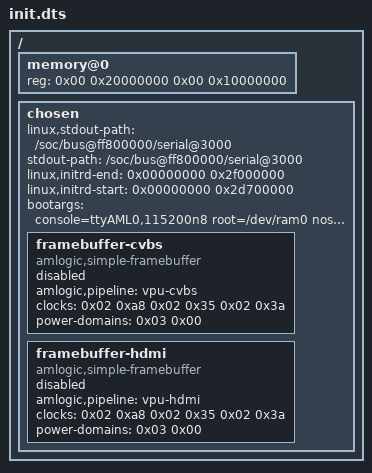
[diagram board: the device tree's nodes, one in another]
/ {
    /delete-node/ memory@0;
    /delete-node/ chosen;

    memory@0 {
		device_type = "memory";
		reg = <0x00 0x20000000 0x00 0x10000000>;
	};

	chosen {
		#address-cells = <0x02>;
		#size-cells = <0x02>;
		ranges;
        linux,stdout-path = "/soc/bus@ff800000/serial@3000";
        stdout-path = "/soc/bus@ff800000/serial@3000";
		linux,initrd-end = <0x00000000 0x2f000000>;
        linux,initrd-start = <0x00000000 0x2d700000>;
        bootargs = "console=ttyAML0,115200n8 root=/dev/ram0 nosmp rw loglevel=8 pci=nomsi earlyprintk=serial maxcpus=1";

		framebuffer-cvbs {
			compatible = "amlogic,simple-framebuffer\0simple-framebuffer";
			amlogic,pipeline = "vpu-cvbs";
			clocks = <0x02 0xa8 0x02 0x35 0x02 0x3a>;
			status = "disabled";
			power-domains = <0x03 0x00>;
		};

		framebuffer-hdmi {
			compatible = "amlogic,simple-framebuffer\0simple-framebuffer";
			amlogic,pipeline = "vpu-hdmi";
			clocks = <0x02 0xa8 0x02 0x35 0x02 0x3a>;
			status = "disabled";
			power-domains = <0x03 0x00>;
		};
	};
};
